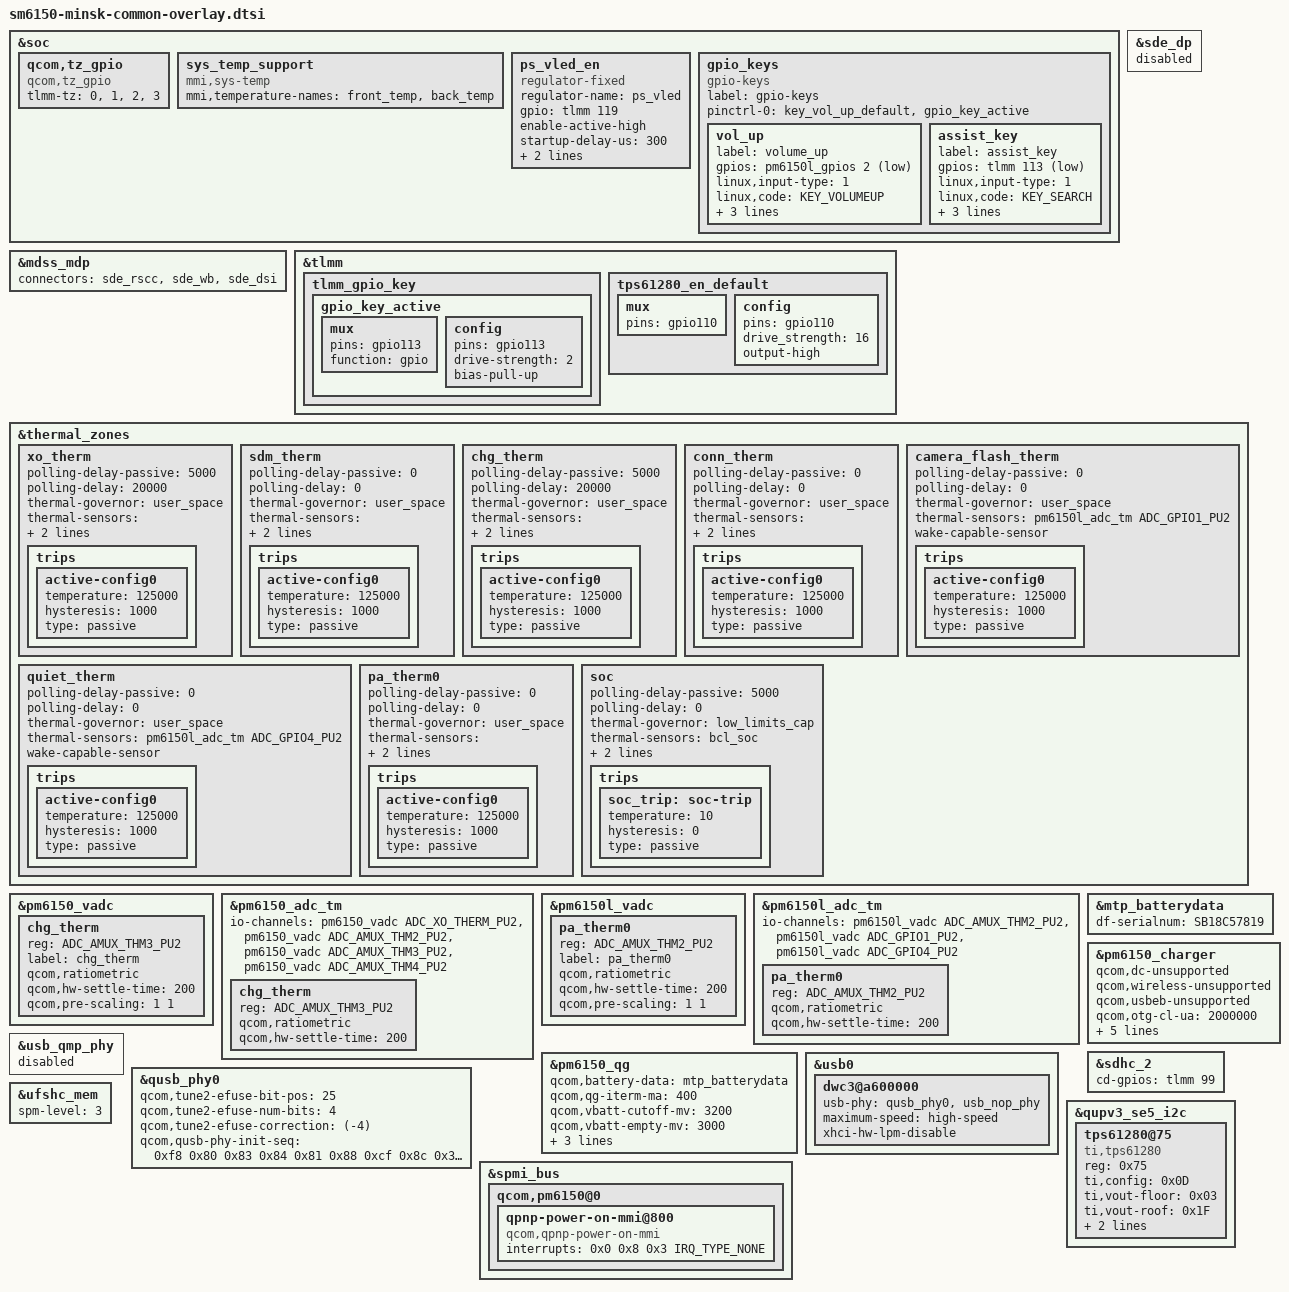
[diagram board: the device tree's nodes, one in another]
/* Copyright (c) 2020, The Linux Foundation. All rights reserved.
 *
 * This program is free software; you can redistribute it and/or modify
 * it under the terms of the GNU General Public License version 2 and
 * only version 2 as published by the Free Software Foundation.
 *
 * This program is distributed in the hope that it will be useful,
 * but WITHOUT ANY WARRANTY; without even the implied warranty of
 * MERCHANTABILITY or FITNESS FOR A PARTICULAR PURPOSE.  See the
 * GNU General Public License for more details.
 */

#include "sm6150-moto-common-overlay.dtsi"
#include "sm6150-camera-sensor-mot-minsk-overlay.dtsi"
#include "minsk-panel.dtsi"
#include "minsk-touchscreen.dtsi"
#include "sm6150-minsk-sensor-overlay.dtsi"
#include "sm6150-minsk-fps-overlay.dtsi"
#include "sm6150-audio-overlay.dtsi"
#include "sm6150-minsk-audio-overlay.dtsi"

&soc {
	qcom,tz_gpio {
		compatible = "qcom,tz_gpio";
		tlmm-tz = <0>,
			<1>,
			<2>,
			<3>;
	};
};

&sde_dp {
	status = "disabled";
};

&mdss_mdp {
       connectors = <&sde_rscc &sde_wb &sde_dsi>;
};

&tlmm{
       /* Pinctrl setting for assist key */
	tlmm_gpio_key {
		gpio_key_active: gpio_key_active {
			mux {
				pins = "gpio113";
				function = "gpio";
			};

			config {
				pins = "gpio113";
				drive-strength = <2>;
				bias-pull-up;
			};
		};
	};

        tps61280_en_default: tps61280_en_default {
               mux {
                        pins = "gpio110";
               };
               config {
                        pins = "gpio110";
                        drive_strength = <16>;
                        output-high;
              };
        };
};

&soc {
	sys_temp_support {
		compatible = "mmi,sys-temp";
		mmi,temperature-names = "front_temp",
			"back_temp";
		status = "ok";
	};

	ps_vled_en: ps_vled_en {
		compatible = "regulator-fixed";
		regulator-name = "ps_vled";
		gpio = <&tlmm 119 0>;
		enable-active-high;
		startup-delay-us = <300>;
		regulator-boot-on;
		regulator-always-on;
	};

	gpio_keys {
		compatible = "gpio-keys";
		label = "gpio-keys";

		pinctrl-names = "default";
		pinctrl-0 = <&key_vol_up_default &gpio_key_active>;

		vol_up {
			label = "volume_up";
			gpios = <&pm6150l_gpios 2 GPIO_ACTIVE_LOW>;
			linux,input-type = <1>;
			linux,code = <KEY_VOLUMEUP>;
			linux,can-disable;
			debounce-interval = <15>;
			gpio-key,wakeup;
		};

		assist_key{
			label = "assist_key";
			gpios = <&tlmm 113 GPIO_ACTIVE_LOW>;
			linux,input-type = <1>;
			linux,code = <KEY_SEARCH>;
			debounce-interval = <15>;
			linux,can-disable;
			gpio-key,wakeup;
		};
	};
};

&thermal_zones {
	xo_therm {
		polling-delay-passive = <5000>;
		polling-delay = <20000>;
		thermal-governor = "user_space";
		thermal-sensors = <&pm6150_adc_tm ADC_XO_THERM_PU2>;
		wake-capable-sensor;
		trips {
			active-config0 {
				temperature = <125000>;
				hysteresis = <1000>;
				type = "passive";
			};
		};
	};

	sdm_therm {
		polling-delay-passive = <0>;
		polling-delay = <0>;
		thermal-governor = "user_space";
		thermal-sensors = <&pm6150_adc_tm ADC_AMUX_THM2_PU2>;
		wake-capable-sensor;
		trips {
			active-config0 {
				temperature = <125000>;
				hysteresis = <1000>;
				type = "passive";
			};
		};
	};

	chg_therm {
		polling-delay-passive = <5000>;
		polling-delay = <20000>;
		thermal-governor = "user_space";
		thermal-sensors = <&pm6150_adc_tm ADC_AMUX_THM3_PU2>;
		wake-capable-sensor;
		trips {
			active-config0 {
				temperature = <125000>;
				hysteresis = <1000>;
				type = "passive";
			};
		};
	};

	conn_therm {
		polling-delay-passive = <0>;
		polling-delay = <0>;
		thermal-governor = "user_space";
		thermal-sensors = <&pm6150_adc_tm ADC_AMUX_THM4_PU2>;
		wake-capable-sensor;
		trips {
			active-config0 {
				temperature = <125000>;
				hysteresis = <1000>;
				type = "passive";
			};
		};
	};

	camera_flash_therm {
		polling-delay-passive = <0>;
		polling-delay = <0>;
		thermal-governor = "user_space";
		thermal-sensors = <&pm6150l_adc_tm ADC_GPIO1_PU2>;
		wake-capable-sensor;
		trips {
			active-config0 {
				temperature = <125000>;
				hysteresis = <1000>;
				type = "passive";
			};
		};
	};

	quiet_therm {
		polling-delay-passive = <0>;
		polling-delay = <0>;
		thermal-governor = "user_space";
		thermal-sensors = <&pm6150l_adc_tm ADC_GPIO4_PU2>;
		wake-capable-sensor;
		trips {
			active-config0 {
				temperature = <125000>;
				hysteresis = <1000>;
				type = "passive";
			};
		};
	};

	pa_therm0 {
		polling-delay-passive = <0>;
		polling-delay = <0>;
		thermal-governor = "user_space";
		thermal-sensors = <&pm6150l_adc_tm ADC_AMUX_THM2_PU2>;
		wake-capable-sensor;
		trips {
			active-config0 {
				temperature = <125000>;
				hysteresis = <1000>;
				type = "passive";
			};
		};
	};

	soc {
		polling-delay-passive = <5000>;
		polling-delay = <0>;
		thermal-governor = "low_limits_cap";
		thermal-sensors = <&bcl_soc>;
		wake-capable-sensor;
		tracks-low;

		trips {
			soc_trip:soc-trip {
				temperature = <10>;
				hysteresis = <0>;
				type = "passive";
			};
		};
	};
};

&pm6150_vadc {
	chg_therm {
		reg = <ADC_AMUX_THM3_PU2>;
		label = "chg_therm";
		qcom,ratiometric;
		qcom,hw-settle-time = <200>;
		qcom,pre-scaling = <1 1>;
	};
};

&pm6150_adc_tm {
	io-channels = <&pm6150_vadc ADC_XO_THERM_PU2>,
			<&pm6150_vadc ADC_AMUX_THM2_PU2>,
			<&pm6150_vadc ADC_AMUX_THM3_PU2>,
			<&pm6150_vadc ADC_AMUX_THM4_PU2>;

	/* Channel nodes */
	chg_therm {
		reg = <ADC_AMUX_THM3_PU2>;
		qcom,ratiometric;
		qcom,hw-settle-time = <200>;
	};
};

&pm6150l_vadc {
	pa_therm0 {
		reg = <ADC_AMUX_THM2_PU2>;
		label = "pa_therm0";
		qcom,ratiometric;
		qcom,hw-settle-time = <200>;
		qcom,pre-scaling = <1 1>;
	};
};

&pm6150l_adc_tm {
	io-channels = <&pm6150l_vadc ADC_AMUX_THM2_PU2>,
			<&pm6150l_vadc ADC_GPIO1_PU2>,
			<&pm6150l_vadc ADC_GPIO4_PU2>;
	/* Channel nodes */
	pa_therm0 {
		reg = <ADC_AMUX_THM2_PU2>;
		qcom,ratiometric;
		qcom,hw-settle-time = <200>;
	};
};

&mtp_batterydata {
	df-serialnum = "SB18C57819";
	#include "qg-batterydata-kx50-amperex-4000mah.dtsi"
	#include "qg-batterydata-kx50-swd-4000mah.dtsi"
};

&pm6150_charger {
	qcom,dc-unsupported;
	qcom,wireless-unsupported;
	qcom,usbeb-unsupported;
	qcom,otg-cl-ua = <2000000>;
	qcom,dcp-power-max = <10000>;/*unit W*/
	qcom,iterm-ma = <194>;
	qcom,mmi-temp-zones = <0 4200 776 0>,
				<10 4200 1940 776>,
				<15 0 1940 1940>,
				<45 4200 3600 2500>,
				<60 4200 1940 0>;
};

&pm6150_qg {
	qcom,battery-data = <&mtp_batterydata>;
	qcom,qg-iterm-ma = <400>;
	qcom,vbatt-cutoff-mv = <3200>;
	qcom,vbatt-empty-mv = <3000>;
	qcom,vbatt-empty-cold-mv = <3000>;
	qcom,s3-entry-ibat-ua = <35000>;
	qcom,s3-exit-ibat-ua = <50000>;
};

&usb_qmp_phy {
	status = "disabled";
};

&usb0 {
	dwc3@a600000 {
		usb-phy = <&qusb_phy0>, <&usb_nop_phy>;
		maximum-speed = "high-speed";
		xhci-hw-lpm-disable;
	};
};

&qusb_phy0 {
	qcom,tune2-efuse-bit-pos = <25>;
	qcom,tune2-efuse-num-bits = <4>;
	qcom,tune2-efuse-correction = <(-4)>;
	qcom,qusb-phy-init-seq = <0xf8 0x80
				0x83 0x84
				0x81 0x88
				0xcf 0x8c
				0x30 0x08
				0x79 0x0c
				0x21 0x10
				0x14 0x9c
				0x9f 0x1c
				0x00 0x18>;
};

&sdhc_2 {
	cd-gpios = <&tlmm 99 0>;
};

&qupv3_se5_i2c {
	status = "okay";

        tps61280@75 {
                compatible = "ti,tps61280";
                reg = <0x75>;
                ti,config = <0x0D>;
                ti,vout-floor = <0x03>;
                ti,vout-roof = <0x1F>;
                ti,ilim = <0x0D>;
                pinctrl-names = "default";
                pinctrl-0 = <&tps61280_en_default>;
        };
};

&spmi_bus {
	qcom,pm6150@0 {
		qpnp-power-on-mmi@800 {
			compatible = "qcom,qpnp-power-on-mmi";
			interrupts = <0x0 0x8 0x3 IRQ_TYPE_NONE>;
			interrupt-names = "kpdpwr-bark";
		};
	};
};

&ufshc_mem {
	spm-level = <3>;
};
